# MIMXRT1062 register map
Vendor: nxp.com; File version: 1.0
CPU: CM7 r0p1, little endian, MPU, FPU, VTOR, 4 interrupt priority bits
Registers are 32-bit, read-write, reset 0x0 unless marked. A register's access mark holds for its fields unless they carry their own. Offsets are from the block's base; [hi:lo] are bit positions; {n}, {i} and the like mark numbered series.

## XBARB2 — Crossbar Switch
Base 0x403C0000; register names take the prefix XBARB2_
Same registers: XBARB3 0x403C4000 (register names take the prefix XBARB3_)
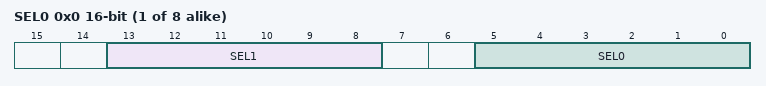
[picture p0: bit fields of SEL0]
{0x0+2i} SEL{i} 16-bit (i=0..7) — Crossbar B Select Register {i}
  [13:8] SEL{2i+1} — Input (XBARB_INn) to be muxed to XBARB_OUT{2i+1} (refer to Functional Description section for input/output assignment)
  [5:0] SEL{2i} — Input (XBARB_INn) to be muxed to XBARB_OUT{2i} (refer to Functional Description section for input/output assignment)

## BEE — Bus Encryption Engine
Base 0x403EC000; register names take the prefix BEE_
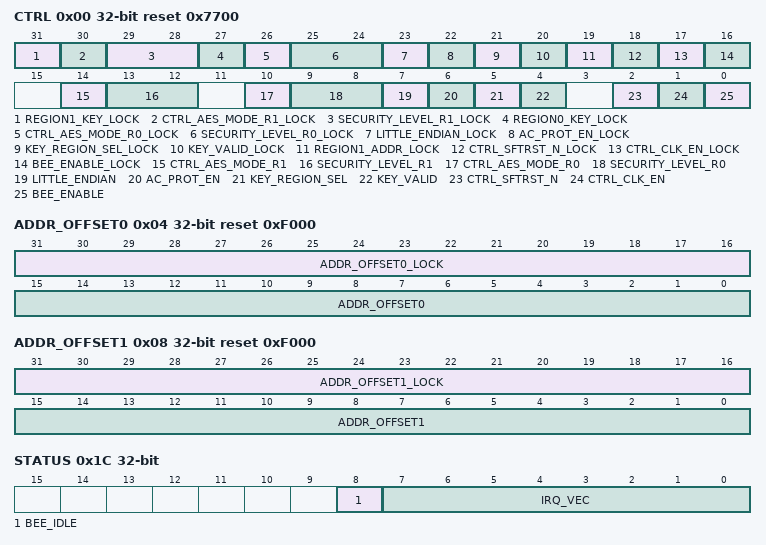
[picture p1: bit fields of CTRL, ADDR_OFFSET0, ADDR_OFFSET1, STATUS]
0x00 CTRL reset 0x7700 — BEE Control Register
  [31] REGION1_KEY_LOCK — Lock bit for region1 AES key
  [30] CTRL_AES_MODE_R1_LOCK — Lock bit for region1 ctrl_aes_mode
  [29:28] SECURITY_LEVEL_R1_LOCK — Lock bits for security_level_r1
  [27] REGION0_KEY_LOCK — Lock bit for region0 AES key
  [26] CTRL_AES_MODE_R0_LOCK — Lock bit for region0 ctrl_aes_mode
  [25:24] SECURITY_LEVEL_R0_LOCK — Lock bits for security_level_r0
  [23] LITTLE_ENDIAN_LOCK — Lock bit for little_endian
  [22] AC_PROT_EN_LOCK — Lock bit for ac_prot
  [21] KEY_REGION_SEL_LOCK — Lock bit for key_region_sel
  [20] KEY_VALID_LOCK — Lock bit for key_valid
  [19] REGION1_ADDR_LOCK — Lock bit for region1 address boundary
  [18] CTRL_SFTRST_N_LOCK — Lock bit for ctrl_sftrst
  [17] CTRL_CLK_EN_LOCK — Lock bit for ctrl_clk_en
  [16] BEE_ENABLE_LOCK — Lock bit for bee_enable
  [14] CTRL_AES_MODE_R1 — AES mode of region1
    0=ECB; 1=CTR
  [13:12] SECURITY_LEVEL_R1 — Security level of the allowed access for memory region1
  [10] CTRL_AES_MODE_R0 — AES mode of region0
    0=ECB; 1=CTR
  [9:8] SECURITY_LEVEL_R0 — Security level of the allowed access for memory region0
  [7] LITTLE_ENDIAN — Endian swap control for the 16 bytes input and output data of AES core.
    0=The input and output data of the AES core is swapped as below: {B15,B14,B13,B12,B11,B10,B9,B8, B7,B6,B5,B4,B3,B2,B1,B0} swap to {B0,B1,B2,B3,B4,B5,B6,B7, B8,B9,B10,B11,B12,B13,B14,B15}, where B0~B15 refers to Byte0 to Byte15; 1=The input and output data of AES core is not swapped
  [6] AC_PROT_EN — Enable access permission control When AC_PROT_EN is asserted, all encrypted regions are limited to be ARM core access only
  [5] KEY_REGION_SEL — AES key region select
    0=Load AES key for region0; 1=Load AES key for region1
  [4] KEY_VALID — AES-128 key is ready
  [2] CTRL_SFTRST_N — Soft reset input, low active
  [1] CTRL_CLK_EN — Clock enable input, low inactive
  [0] BEE_ENABLE — BEE enable bit
    0=Disable BEE; 1=Enable BEE
0x04 ADDR_OFFSET0 reset 0xF000
  [31:16] ADDR_OFFSET0_LOCK — Lock bits for addr_offset0
  [15:0] ADDR_OFFSET0 — Signed offset for BEE region 0
0x08 ADDR_OFFSET1 reset 0xF000
  [31:16] ADDR_OFFSET1_LOCK — Lock bits for addr_offset1
  [15:0] ADDR_OFFSET1 — Signed offset for BEE region 1
{0xC+4i} AES_KEY0_W{i} (i=0..3)
  [31:0] KEY{i} — AES 128 key from software
0x1C STATUS reset not defined
  [8] BEE_IDLE ro — 1'b1: BEE is idle; 1'b0: BEE is active
  [7:0] IRQ_VEC write-1-clears — bit 7: Protected region-3 access violation bit 6: Protected region-2 access violation bit 5: Protected region-1 access violation bit 4: Protected region-0 access violation bit 3: Region-1 read channel security violation bit 2: Read channel illegal access detected bit 1: Region-0 read channel security violation bit 0: Disable abort
{0x20+4i} CTR_NONCE0_W{i} wo (i=0..3)
  [31:0] NONCE{i:02} — Nonce0 from software for CTR, for region0. Nonce0={Nonce03,Nonce02,Nonce01,Nonce00}
{0x30+4i} CTR_NONCE1_W{i} wo (i=0..3)
  [31:0] NONCE{i+10} — Nonce1 from software for CTR, for region1. Nonce1={Nonce13,Nonce12,Nonce11,Nonce10}
0x40 REGION1_TOP
  [31:0] REGION1_TOP — Address upper limit of region1
0x44 REGION1_BOT
  [31:0] REGION1_BOT — Address lower limit of region1
